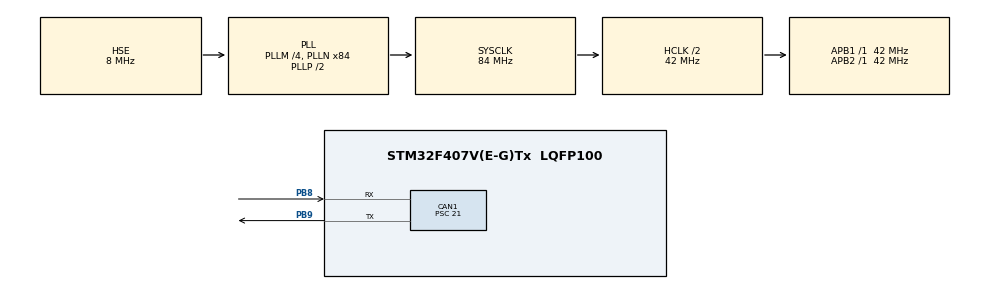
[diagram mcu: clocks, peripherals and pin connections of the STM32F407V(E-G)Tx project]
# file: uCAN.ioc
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CAN1.BS1=CAN_BS1_13TQ
CAN1.BS2=CAN_BS2_2TQ
CAN1.CalculateBaudRate=125000
CAN1.CalculateTimeBit=8000
CAN1.CalculateTimeQuantum=500.0
CAN1.Prescaler=21
Mcu.Family=STM32F4
Mcu.Name=STM32F407V(E-G)Tx
Mcu.Package=LQFP100
NVIC.CAN1_RX0_IRQn=true\:0\:0\:false\:false\:true\:true\:true\:true
NVIC.PriorityGroup=NVIC_PRIORITYGROUP_4
PB8.Mode=CAN_Activate
PB8.Signal=CAN1_RX
PB9.Mode=CAN_Activate
PB9.Signal=CAN1_TX
PH0-OSC_IN.Mode=HSE-External-Oscillator
PH0-OSC_IN.Signal=RCC_OSC_IN
PH1-OSC_OUT.Mode=HSE-External-Oscillator
PH1-OSC_OUT.Signal=RCC_OSC_OUT
ProjectManager.HeapSize=0x200
ProjectManager.StackSize=0x400
ProjectManager.TargetToolchain=STM32CubeIDE
RCC.48MHZClocksFreq_Value=42000000
RCC.AHBCLKDivider=RCC_SYSCLK_DIV2
RCC.AHBFreq_Value=42000000
RCC.APB1Freq_Value=42000000
RCC.APB1TimFreq_Value=42000000
RCC.APB2Freq_Value=42000000
RCC.APB2TimFreq_Value=42000000
RCC.CortexFreq_Value=42000000
RCC.HCLKFreq_Value=42000000
RCC.HSE_VALUE=8000000
RCC.HSI_VALUE=16000000
RCC.LSE_VALUE=32768
RCC.PLLM=4
RCC.PLLN=84
RCC.PLLSourceVirtual=RCC_PLLSOURCE_HSE
RCC.SYSCLKFreq_VALUE=84000000
RCC.SYSCLKSource=RCC_SYSCLKSOURCE_PLLCLK
RCC.VCOOutputFreq_Value=168000000
board=custom

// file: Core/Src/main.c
/* USER CODE BEGIN Header */
/**
 ******************************************************************************
 * @file           : main.c
 * @brief          : Main program body
 ******************************************************************************
 * @attention
 *
 * Copyright (c) 2025 STMicroelectronics.
 * All rights reserved.
 *
 * This software is licensed under terms that can be found in the LICENSE file
 * in the root directory of this software component.
 * If no LICENSE file comes with this software, it is provided AS-IS.
 *
 ******************************************************************************
 */
/* USER CODE END Header */
#include "main.h"

/* USER CODE BEGIN PM */
#define txPacketCount 2
#define rxPacketCount 2
/* USER CODE END PM */

CAN_HandleTypeDef hcan1;

/* USER CODE BEGIN PV */
UCAN_HandleTypeDef ucan1;
UCAN_Packet txpackets[txPacketCount];
UCAN_Packet rxpackets[rxPacketCount];

UCAN_Client clients[3] = {
		{.id = 0x100U},
		{.id = 0x200U},
		{.id = 0x300U},
};

uint8_t byte1;
uint8_t byte1_2;
uint8_t byte1_3;
uint16_t byte2;
uint32_t byte4;
uint32_t byte4_2;

/* USER CODE END PV */

void SystemClock_Config(void);
static void MX_GPIO_Init(void);
static void MX_CAN1_Init(void);
/* USER CODE BEGIN PFP */
static void UCAN1_Init(void);
static void UCAN1_Start(void);
/* USER CODE END PFP */

int main(void)
{

  /* MCU Configuration--------------------------------------------------------*/

  /* Reset of all peripherals, Initializes the Flash interface and the Systick. */
  HAL_Init();

  /* Configure the system clock */
  SystemClock_Config();

  /* Initialize all configured peripherals */
  MX_GPIO_Init();
  MX_CAN1_Init();
  /* USER CODE BEGIN 2 */
	UCAN1_Init();
	UCAN1_Start();
  /* USER CODE END 2 */

  /* Infinite loop */
  /* USER CODE BEGIN WHILE */
	while (1) {
		uCAN_Handshake(&ucan1);
//		byte4_2++;
//		byte1_3++;
//		byte4++;
//		byte1_2--;
		HAL_Delay(50);
		uCAN_SendAll(&ucan1);

    /* USER CODE END WHILE */

	}
}

void SystemClock_Config(void)
{
  RCC_OscInitTypeDef RCC_OscInitStruct = {0};
  RCC_ClkInitTypeDef RCC_ClkInitStruct = {0};

  /** Configure the main internal regulator output voltage
  */
  __HAL_RCC_PWR_CLK_ENABLE();
  __HAL_PWR_VOLTAGESCALING_CONFIG(PWR_REGULATOR_VOLTAGE_SCALE1);

  /** Initializes the RCC Oscillators according to the specified parameters
  * in the RCC_OscInitTypeDef structure.
  */
  RCC_OscInitStruct.OscillatorType = RCC_OSCILLATORTYPE_HSE;
  RCC_OscInitStruct.HSEState = RCC_HSE_ON;
  RCC_OscInitStruct.PLL.PLLState = RCC_PLL_ON;
  RCC_OscInitStruct.PLL.PLLSource = RCC_PLLSOURCE_HSE;
  RCC_OscInitStruct.PLL.PLLM = 4;
  RCC_OscInitStruct.PLL.PLLN = 84;
  RCC_OscInitStruct.PLL.PLLP = RCC_PLLP_DIV2;
  RCC_OscInitStruct.PLL.PLLQ = 4;
  if (HAL_RCC_OscConfig(&RCC_OscInitStruct) != HAL_OK)
  {
    Error_Handler();
  }

  /** Initializes the CPU, AHB and APB buses clocks
  */
  RCC_ClkInitStruct.ClockType = RCC_CLOCKTYPE_HCLK|RCC_CLOCKTYPE_SYSCLK
                              |RCC_CLOCKTYPE_PCLK1|RCC_CLOCKTYPE_PCLK2;
  RCC_ClkInitStruct.SYSCLKSource = RCC_SYSCLKSOURCE_PLLCLK;
  RCC_ClkInitStruct.AHBCLKDivider = RCC_SYSCLK_DIV2;
  RCC_ClkInitStruct.APB1CLKDivider = RCC_HCLK_DIV1;
  RCC_ClkInitStruct.APB2CLKDivider = RCC_HCLK_DIV1;

  if (HAL_RCC_ClockConfig(&RCC_ClkInitStruct, FLASH_LATENCY_1) != HAL_OK)
  {
    Error_Handler();
  }
}

static void MX_CAN1_Init(void)
{

  hcan1.Instance = CAN1;
  hcan1.Init.Prescaler = 21;
  hcan1.Init.Mode = CAN_MODE_NORMAL;
  hcan1.Init.SyncJumpWidth = CAN_SJW_1TQ;
  hcan1.Init.TimeSeg1 = CAN_BS1_13TQ;
  hcan1.Init.TimeSeg2 = CAN_BS2_2TQ;
  hcan1.Init.TimeTriggeredMode = DISABLE;
  hcan1.Init.AutoBusOff = DISABLE;
  hcan1.Init.AutoWakeUp = DISABLE;
  hcan1.Init.AutoRetransmission = DISABLE;
  hcan1.Init.ReceiveFifoLocked = DISABLE;
  hcan1.Init.TransmitFifoPriority = DISABLE;
  if (HAL_CAN_Init(&hcan1) != HAL_OK)
  {
    Error_Handler();
  }

}

static void MX_GPIO_Init(void)
{

  /* GPIO Ports Clock Enable */
  __HAL_RCC_GPIOH_CLK_ENABLE();
  __HAL_RCC_GPIOB_CLK_ENABLE();

}

/* USER CODE BEGIN 4 */
static void UCAN1_Init(void) {
	ucan1.hcan = &hcan1;
	ucan1.node.masterId = 0x050;
	ucan1.node.selfId = 0x050;
	ucan1.node.role = UCAN_ROLE_MASTER;
	ucan1.node.clients = clients;
	ucan1.node.clientCount = UCAN_CLIENT_COUNT(clients);
	ucan1.txHolder.packets = txpackets;
	ucan1.txHolder.count = UCAN_PACKET_COUNT(txpackets);
	ucan1.rxHolder.packets = rxpackets;
	ucan1.rxHolder.count = UCAN_PACKET_COUNT(rxpackets);

	if (uCAN_Init(&ucan1) != UCAN_OK) {
		Error_Handler();
	}
}

static void UCAN1_Start(void) {

	UCAN_PacketConfig txConfigPacket[txPacketCount] = {
			{ .id = 0x245U, .item_count = 2,
					.items = {
					{ .type = UCAN_U32, .ptr = &byte4 },
					{ .type = UCAN_U8, .ptr = &byte1_2 },
			}

			},

			{ .id = 0x240U, .item_count = 3,
					.items = {
							{ .type = UCAN_U32, .ptr = &byte4},
							{ .type = UCAN_U8,  .ptr = &byte1},
							{ .type = UCAN_U8,  .ptr = &byte1_2},
					}
			},

	};

	UCAN_PacketConfig rxConfigPacket[rxPacketCount] = {

			{ .id = 0x250U, .item_count = 2,
					.items = {
							{ .type = UCAN_U8, .ptr = &byte1_3 },
							{ .type = UCAN_U32, .ptr = &byte4_2 },
			}

			},
			{ .id = 0x350U, .item_count = 2,
					.items = {
							{ .type = UCAN_U32, .ptr = &byte4 },
							{ .type = UCAN_U32, .ptr = &byte4_2 },
					}
			},
	};

	UCAN_Config ucanConfig;

	ucanConfig.txPacketList = txConfigPacket;
	ucanConfig.rxPacketList = rxConfigPacket;

	if (uCAN_Start(&ucan1, &ucanConfig) != UCAN_OK) {
		Error_Handler();
	}
}
/* USER CODE END 4 */

void Error_Handler(void)
{
	__disable_irq();
	while (1) {
	}
}
